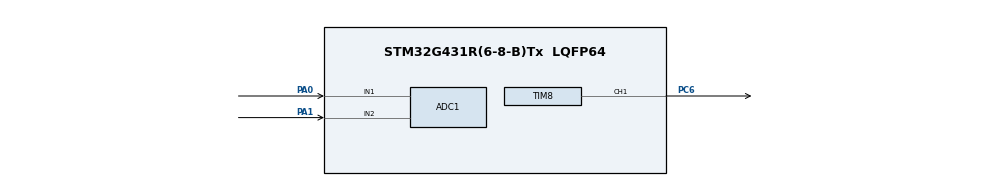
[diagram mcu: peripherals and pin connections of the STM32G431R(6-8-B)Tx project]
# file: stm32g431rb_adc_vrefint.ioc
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ADC1.Channel-0\#ChannelRegularConversion=ADC_CHANNEL_1
ADC1.Channel-1\#ChannelRegularConversion=ADC_CHANNEL_2
ADC1.Channel-2\#ChannelRegularConversion=ADC_CHANNEL_VREFINT
ADC1.DMAContinuousRequests=ENABLE
ADC1.ExternalTrigConv=ADC_EXTERNALTRIG_T8_TRGO
ADC1.NbrOfConversion=3
ADC1.NbrOfConversionFlag=1
ADC1.OffsetNumber-0\#ChannelRegularConversion=ADC_OFFSET_NONE
ADC1.OffsetNumber-1\#ChannelRegularConversion=ADC_OFFSET_NONE
ADC1.OffsetNumber-2\#ChannelRegularConversion=ADC_OFFSET_NONE
ADC1.Rank-0\#ChannelRegularConversion=1
ADC1.Rank-1\#ChannelRegularConversion=2
ADC1.Rank-2\#ChannelRegularConversion=3
ADC1.SamplingTime-0\#ChannelRegularConversion=ADC_SAMPLETIME_12CYCLES_5
ADC1.SamplingTime-1\#ChannelRegularConversion=ADC_SAMPLETIME_12CYCLES_5
ADC1.SamplingTime-2\#ChannelRegularConversion=ADC_SAMPLETIME_247CYCLES_5
ADC1.master=1
Dma.ADC1.0.Direction=DMA_PERIPH_TO_MEMORY
Dma.ADC1.0.EventEnable=DISABLE
Dma.ADC1.0.Instance=DMA1_Channel1
Dma.ADC1.0.MemDataAlignment=DMA_MDATAALIGN_HALFWORD
Dma.ADC1.0.MemInc=DMA_MINC_ENABLE
Dma.ADC1.0.Mode=DMA_CIRCULAR
Dma.ADC1.0.PeriphDataAlignment=DMA_PDATAALIGN_HALFWORD
Dma.ADC1.0.PeriphInc=DMA_PINC_DISABLE
Dma.ADC1.0.Polarity=HAL_DMAMUX_REQ_GEN_RISING
Dma.ADC1.0.Priority=DMA_PRIORITY_LOW
Dma.ADC1.0.RequestNumber=1
Dma.ADC1.0.SignalID=NONE
Dma.ADC1.0.SyncEnable=DISABLE
Dma.ADC1.0.SyncPolarity=HAL_DMAMUX_SYNC_NO_EVENT
Dma.ADC1.0.SyncRequestNumber=1
Dma.ADC1.0.SyncSignalID=NONE
Dma.Request0=ADC1
Mcu.Family=STM32G4
Mcu.Name=STM32G431R(6-8-B)Tx
Mcu.Package=LQFP64
NVIC.DMA1_Channel1_IRQn=true\:0\:0\:false\:false\:true\:false\:true\:true
NVIC.PriorityGroup=NVIC_PRIORITYGROUP_4
PA0.Mode=IN1-Single-Ended
PA0.Signal=ADC1_IN1
PA1.Mode=IN2-Single-Ended
PA1.Signal=ADC1_IN2
PC6.Signal=S_TIM8_CH1
ProjectManager.HeapSize=0x200
ProjectManager.StackSize=0x400
ProjectManager.TargetToolchain=STM32CubeIDE
RCC.ADC12Freq_Value=170000000
RCC.AHBFreq_Value=170000000
RCC.APB1Freq_Value=170000000
RCC.APB1TimFreq_Value=170000000
RCC.APB2Freq_Value=170000000
RCC.APB2TimFreq_Value=170000000
RCC.CortexFreq_Value=170000000
RCC.EXTERNAL_CLOCK_VALUE=12288000
RCC.HCLKFreq_Value=170000000
RCC.HSE_VALUE=8000000
RCC.HSI48_VALUE=48000000
RCC.HSI_VALUE=16000000
RCC.LSE_VALUE=32768
RCC.PLLM=RCC_PLLM_DIV4
RCC.PLLN=85
RCC.SYSCLKFreq_VALUE=170000000
RCC.SYSCLKSource=RCC_SYSCLKSOURCE_PLLCLK
RCC.USBFreq_Value=170000000
RCC.VCOOutputFreq_Value=340000000
SH.S_TIM8_CH1.0=TIM8_CH1,PWM Generation1 CH1
TIM8.Channel-PWM\ Generation1\ CH1=TIM_CHANNEL_1
TIM8.PeriodNoDither=1000
TIM8.Prescaler=170
TIM8.PulseNoDither_1=300
TIM8.TIM_MasterOutputTrigger=TIM_TRGO_OC1REF
VP_ADC1_Vref_Input.Mode=IN-Vrefint
VP_SYS_VS_DBSignals.Mode=DisableDeadBatterySignals
VP_TIM8_VS_ClockSourceINT.Mode=Internal
board=custom

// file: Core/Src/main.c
/* USER CODE BEGIN Header */
/**
  ******************************************************************************
  * @file           : main.c
  * @brief          : Main program body
  ******************************************************************************
  * @attention
  *
  * <h2><center>&copy; Copyright (c) 2021 STMicroelectronics.
  * All rights reserved.</center></h2>
  *
  * This software component is licensed by ST under BSD 3-Clause license,
  * the "License"; You may not use this file except in compliance with the
  * License. You may obtain a copy of the License at:
  *                        opensource.org/licenses/BSD-3-Clause
  *
  ******************************************************************************
  */
/* USER CODE END Header */
#include "main.h"
#include "adc.h"
#include "dma.h"
#include "tim.h"
#include "gpio.h"

void SystemClock_Config(void);

/* USER CODE BEGIN 0 */
void  Activate_ADC(void);
__IO uint16_t adc_converted_values[3];
__IO uint16_t vrefint_converted_value = 0;
__IO uint16_t vdda_milli_volt = 0;
__IO uint16_t is_dma_transfer_completed   = 0;
__IO uint16_t channel1_converted_value = 0;
/* USER CODE END 0 */

int main(void)
{

  /* MCU Configuration--------------------------------------------------------*/

  /* Reset of all peripherals, Initializes the Flash interface and the Systick. */
  LL_APB2_GRP1_EnableClock(LL_APB2_GRP1_PERIPH_SYSCFG);
  LL_APB1_GRP1_EnableClock(LL_APB1_GRP1_PERIPH_PWR);

  /* System interrupt init*/
  NVIC_SetPriorityGrouping(NVIC_PRIORITYGROUP_4);

  /* SysTick_IRQn interrupt configuration */
  NVIC_SetPriority(SysTick_IRQn, NVIC_EncodePriority(NVIC_GetPriorityGrouping(),15, 0));

  /** Disable the internal Pull-Up in Dead Battery pins of UCPD peripheral
  */
  LL_PWR_DisableUCPDDeadBattery();

  /* Configure the system clock */
  SystemClock_Config();

  /* Initialize all configured peripherals */
  MX_GPIO_Init();
  MX_DMA_Init();
  MX_ADC1_Init();
  MX_TIM8_Init();
  /* USER CODE BEGIN 2 */
	Activate_ADC();

  if ((LL_ADC_IsEnabled(ADC1) == 1)               &&
      (LL_ADC_IsDisableOngoing(ADC1) == 0)        &&
      (LL_ADC_REG_IsConversionOngoing(ADC1) == 0)   )
  {
    LL_ADC_REG_StartConversion(ADC1);
  }
  else
  {
    /* Error: ADC conversion start could not be performed */
  }
  /* USER CODE END 2 */

  /* Infinite loop */
  /* USER CODE BEGIN WHILE */
  while (1)
  {
    if(is_dma_transfer_completed == 1)
    {
      vrefint_converted_value = adc_converted_values[2];
      vdda_milli_volt = (VREFINT_CAL_VREF * (*VREFINT_CAL_ADDR)) / vrefint_converted_value;
      channel1_converted_value = (int)((float)vdda_milli_volt * (float)((float)adc_converted_values[0] / 4096.0F));

      is_dma_transfer_completed = 0;
    }
    /* USER CODE END WHILE */

  }
}

void SystemClock_Config(void)
{
  LL_FLASH_SetLatency(LL_FLASH_LATENCY_4);
  while(LL_FLASH_GetLatency() != LL_FLASH_LATENCY_4)
  {
  }
  LL_PWR_EnableRange1BoostMode();
  LL_RCC_HSI_Enable();
   /* Wait till HSI is ready */
  while(LL_RCC_HSI_IsReady() != 1)
  {
  }

  LL_RCC_HSI_SetCalibTrimming(64);
  LL_RCC_PLL_ConfigDomain_SYS(LL_RCC_PLLSOURCE_HSI, LL_RCC_PLLM_DIV_4, 85, LL_RCC_PLLR_DIV_2);
  LL_RCC_PLL_EnableDomain_SYS();
  LL_RCC_PLL_Enable();
   /* Wait till PLL is ready */
  while(LL_RCC_PLL_IsReady() != 1)
  {
  }

  LL_RCC_SetSysClkSource(LL_RCC_SYS_CLKSOURCE_PLL);
  LL_RCC_SetAHBPrescaler(LL_RCC_SYSCLK_DIV_2);
   /* Wait till System clock is ready */
  while(LL_RCC_GetSysClkSource() != LL_RCC_SYS_CLKSOURCE_STATUS_PLL)
  {
  }

  /* Insure 1�s transition state at intermediate medium speed clock based on DWT */
  CoreDebug->DEMCR |= CoreDebug_DEMCR_TRCENA_Msk;
  DWT->CTRL |= DWT_CTRL_CYCCNTENA_Msk;
  DWT->CYCCNT = 0;
  while(DWT->CYCCNT < 100);
  /* Set AHB prescaler*/
  LL_RCC_SetAHBPrescaler(LL_RCC_SYSCLK_DIV_1);
  LL_RCC_SetAPB1Prescaler(LL_RCC_APB1_DIV_1);
  LL_RCC_SetAPB2Prescaler(LL_RCC_APB2_DIV_1);

  LL_Init1msTick(170000000);

  LL_SetSystemCoreClock(170000000);
}

/* USER CODE BEGIN 4 */
#define ADC_DELAY_CALIB_ENABLE_CPU_CYCLES  (LL_ADC_DELAY_CALIB_ENABLE_ADC_CYCLES * 32)

void Activate_ADC(void)
{
  __IO uint32_t wait_loop_index = 0U;
  #if (USE_TIMEOUT == 1)
  uint32_t Timeout = 0U; /* Variable used for timeout management */
  #endif /* USE_TIMEOUT */
  if (LL_ADC_IsEnabled(ADC1) == 0)
  {
    LL_ADC_DisableDeepPowerDown(ADC1);
    LL_ADC_EnableInternalRegulator(ADC1);
    wait_loop_index = ((LL_ADC_DELAY_INTERNAL_REGUL_STAB_US * (SystemCoreClock / (100000 * 2))) / 10);
    while(wait_loop_index != 0)
    {
      wait_loop_index--;
    }

    LL_ADC_StartCalibration(ADC1, LL_ADC_SINGLE_ENDED);

    #if (USE_TIMEOUT == 1)
    Timeout = ADC_CALIBRATION_TIMEOUT_MS;
    #endif /* USE_TIMEOUT */

    while (LL_ADC_IsCalibrationOnGoing(ADC1) != 0)
    {
    #if (USE_TIMEOUT == 1)
      if (LL_SYSTICK_IsActiveCounterFlag())
      {
        if(Timeout-- == 0)
        {
        }
      }
    #endif /* USE_TIMEOUT */
    }

    wait_loop_index = (ADC_DELAY_CALIB_ENABLE_CPU_CYCLES >> 1);
    while(wait_loop_index != 0)
    {
      wait_loop_index--;
    }

    /* Enable ADC */
    LL_ADC_Enable(ADC1);

    /* Poll for ADC ready to convert */
    #if (USE_TIMEOUT == 1)
    Timeout = ADC_ENABLE_TIMEOUT_MS;
    #endif /* USE_TIMEOUT */

    while (LL_ADC_IsActiveFlag_ADRDY(ADC1) == 0)
    {
    #if (USE_TIMEOUT == 1)
      /* Check Systick counter flag to decrement the time-out value */
      if (LL_SYSTICK_IsActiveCounterFlag())
      {
        if(Timeout-- == 0)
        {
        }
      }
    #endif /* USE_TIMEOUT */
    }
  }
}
/* USER CODE END 4 */

void Error_Handler(void)
{
  __disable_irq();
  while (1)
  {
  }
}
